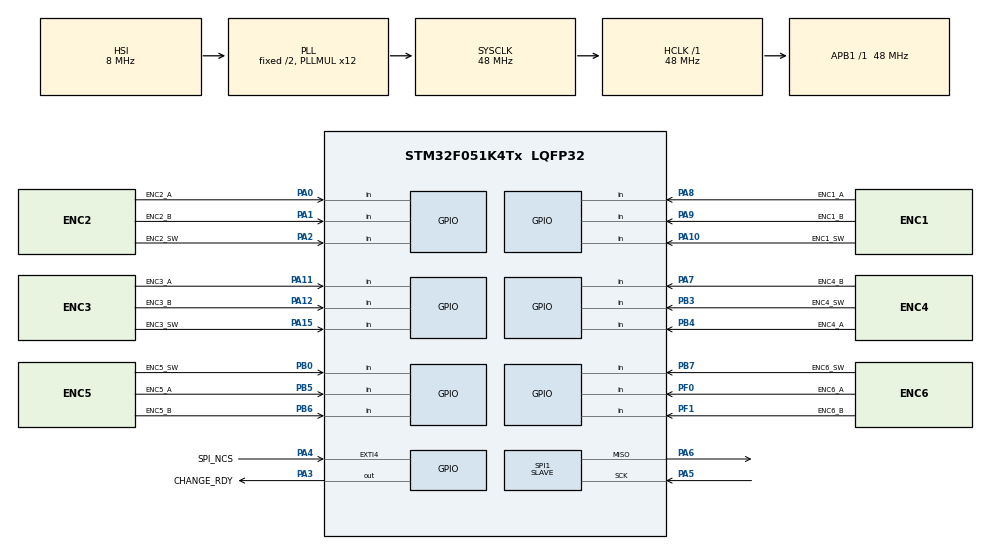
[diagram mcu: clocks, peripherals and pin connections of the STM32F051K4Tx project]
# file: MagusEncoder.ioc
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Dma.Request0=SPI1_TX
Dma.SPI1_TX.0.Direction=DMA_MEMORY_TO_PERIPH
Dma.SPI1_TX.0.Instance=DMA1_Channel3
Dma.SPI1_TX.0.MemDataAlignment=DMA_MDATAALIGN_BYTE
Dma.SPI1_TX.0.MemInc=DMA_MINC_ENABLE
Dma.SPI1_TX.0.Mode=DMA_NORMAL
Dma.SPI1_TX.0.PeriphDataAlignment=DMA_PDATAALIGN_BYTE
Dma.SPI1_TX.0.PeriphInc=DMA_PINC_DISABLE
Dma.SPI1_TX.0.Priority=DMA_PRIORITY_LOW
Mcu.Family=STM32F0
Mcu.Name=STM32F051K4Tx
Mcu.Package=LQFP32
NVIC.DMA1_Channel2_3_IRQn=true\:0\:0\:false\:false\:true\:false\:true
NVIC.EXTI4_15_IRQn=true\:1\:0\:true\:false\:true\:true\:true
NVIC.SPI1_IRQn=true\:1\:0\:true\:false\:true\:true\:true
PA0.GPIO_Label=ENC2_A
PA0.GPIO_PuPd=GPIO_PULLUP
PA0.Signal=GPIO_Input
PA1.GPIO_Label=ENC2_B
PA1.GPIO_PuPd=GPIO_PULLUP
PA1.Signal=GPIO_Input
PA10.GPIO_Label=ENC1_SW
PA10.GPIO_PuPd=GPIO_PULLUP
PA10.Signal=GPIO_Input
PA11.GPIO_Label=ENC3_A
PA11.GPIO_PuPd=GPIO_PULLUP
PA11.Signal=GPIO_Input
PA12.GPIO_Label=ENC3_B
PA12.GPIO_PuPd=GPIO_PULLUP
PA12.Signal=GPIO_Input
PA13.Mode=Serial_Wire
PA13.Signal=SYS_SWDIO
PA14.Mode=Serial_Wire
PA14.Signal=SYS_SWCLK
PA15.GPIO_Label=ENC3_SW
PA15.GPIO_PuPd=GPIO_PULLUP
PA15.Signal=GPIO_Input
PA2.GPIO_Label=ENC2_SW
PA2.GPIO_PuPd=GPIO_PULLUP
PA2.Signal=GPIO_Input
PA3.GPIO_Label=CHANGE_RDY
PA3.PinState=GPIO_PIN_RESET
PA3.Signal=GPIO_Output
PA4.GPIO_Label=SPI_NCS
PA4.GPIO_ModeDefaultEXTI=GPIO_MODE_IT_FALLING
PA4.Signal=GPXTI4
PA5.Mode=TX_Only_Simplex_Unidirect_Slave
PA5.Signal=SPI1_SCK
PA6.Mode=TX_Only_Simplex_Unidirect_Slave
PA6.Signal=SPI1_MISO
PA7.GPIO_Label=ENC4_B
PA7.GPIO_PuPd=GPIO_PULLUP
PA7.Signal=GPIO_Input
PA8.GPIO_Label=ENC1_A
PA8.GPIO_PuPd=GPIO_PULLUP
PA8.Signal=GPIO_Input
PA9.GPIO_Label=ENC1_B
PA9.GPIO_PuPd=GPIO_PULLUP
PA9.Signal=GPIO_Input
PB0.GPIO_Label=ENC5_SW
PB0.GPIO_PuPd=GPIO_PULLUP
PB0.Signal=GPIO_Input
PB3.GPIO_Label=ENC4_SW
PB3.GPIO_PuPd=GPIO_PULLUP
PB3.Signal=GPIO_Input
PB4.GPIO_Label=ENC4_A
PB4.GPIO_PuPd=GPIO_PULLUP
PB4.Signal=GPIO_Input
PB5.GPIO_Label=ENC5_A
PB5.GPIO_PuPd=GPIO_PULLUP
PB5.Signal=GPIO_Input
PB6.GPIO_Label=ENC5_B
PB6.GPIO_PuPd=GPIO_PULLUP
PB6.Signal=GPIO_Input
PB7.GPIO_Label=ENC6_SW
PB7.GPIO_PuPd=GPIO_PULLUP
PB7.Signal=GPIO_Input
PF0-OSC_IN.GPIO_Label=ENC6_A
PF0-OSC_IN.GPIO_PuPd=GPIO_PULLUP
PF0-OSC_IN.Signal=GPIO_Input
PF1-OSC_OUT.GPIO_Label=ENC6_B
PF1-OSC_OUT.GPIO_PuPd=GPIO_PULLUP
PF1-OSC_OUT.Signal=GPIO_Input
ProjectManager.HeapSize=0x200
ProjectManager.StackSize=0x400
ProjectManager.TargetToolchain=MDK-ARM V5
RCC.AHBFreq_Value=48000000
RCC.APB1Freq_Value=48000000
RCC.APB1TimFreq_Value=48000000
RCC.HCLKFreq_Value=48000000
RCC.PLLMUL=RCC_PLL_MUL12
RCC.SYSCLKFreq_VALUE=48000000
RCC.SYSCLKSource=RCC_SYSCLKSOURCE_PLLCLK
SPI1.DataSize=SPI_DATASIZE_8BIT
SPI1.Direction=SPI_DIRECTION_2LINES
SPI1.Mode=SPI_MODE_SLAVE
SPI1.TIMode=SPI_TIMODE_DISABLE
SPI1.VirtualType=VM_SLAVE
board=MagusEncoder

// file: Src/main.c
/* USER CODE BEGIN Header */
/**
  ******************************************************************************
  * @file           : main.c
  * @brief          : Main program body
  ******************************************************************************
  ** This notice applies to any and all portions of this file
  * that are not between comment pairs USER CODE BEGIN and
  * USER CODE END. Other portions of this file, whether
  * inserted by the user or by software development tools
  * are owned by their respective copyright owners.
  *
  * COPYRIGHT(c) 2019 STMicroelectronics
  *
  * Redistribution and use in source and binary forms, with or without modification,
  * are permitted provided that the following conditions are met:
  *   1. Redistributions of source code must retain the above copyright notice,
  *      this list of conditions and the following disclaimer.
  *   2. Redistributions in binary form must reproduce the above copyright notice,
  *      this list of conditions and the following disclaimer in the documentation
  *      and/or other materials provided with the distribution.
  *   3. Neither the name of STMicroelectronics nor the names of its contributors
  *      may be used to endorse or promote products derived from this software
  *      without specific prior written permission.
  *
  * THIS SOFTWARE IS PROVIDED BY THE COPYRIGHT HOLDERS AND CONTRIBUTORS "AS IS"
  * AND ANY EXPRESS OR IMPLIED WARRANTIES, INCLUDING, BUT NOT LIMITED TO, THE
  * IMPLIED WARRANTIES OF MERCHANTABILITY AND FITNESS FOR A PARTICULAR PURPOSE ARE
  * DISCLAIMED. IN NO EVENT SHALL THE COPYRIGHT HOLDER OR CONTRIBUTORS BE LIABLE
  * FOR ANY DIRECT, INDIRECT, INCIDENTAL, SPECIAL, EXEMPLARY, OR CONSEQUENTIAL
  * DAMAGES (INCLUDING, BUT NOT LIMITED TO, PROCUREMENT OF SUBSTITUTE GOODS OR
  * SERVICES; LOSS OF USE, DATA, OR PROFITS; OR BUSINESS INTERRUPTION) HOWEVER
  * CAUSED AND ON ANY THEORY OF LIABILITY, WHETHER IN CONTRACT, STRICT LIABILITY,
  * OR TORT (INCLUDING NEGLIGENCE OR OTHERWISE) ARISING IN ANY WAY OUT OF THE USE
  * OF THIS SOFTWARE, EVEN IF ADVISED OF THE POSSIBILITY OF SUCH DAMAGE.
  *
  ******************************************************************************
  */
/* USER CODE END Header */
#include "main.h"

/* USER CODE BEGIN Includes */
#include "MagusEncoder.h"
/* USER CODE END Includes */

SPI_HandleTypeDef hspi1;
DMA_HandleTypeDef hdma_spi1_tx;

/* USER CODE BEGIN PV */
/* Private variables ---------------------------------------------------------*/

/* USER CODE END PV */

void SystemClock_Config(void);
static void MX_GPIO_Init(void);
static void MX_DMA_Init(void);
static void MX_SPI1_Init(void);
/* USER CODE BEGIN PFP */
/* Private function prototypes -----------------------------------------------*/

/* USER CODE END PFP */

int main(void)
{

  /* MCU Configuration--------------------------------------------------------*/

  /* Reset of all peripherals, Initializes the Flash interface and the Systick. */
  HAL_Init();

  /* Configure the system clock */
  SystemClock_Config();

  /* Initialize all configured peripherals */
  MX_GPIO_Init();
  MX_DMA_Init();
  MX_SPI1_Init();

  /* Infinite loop */
  /* USER CODE BEGIN WHILE */
  while (1)
  {
    Encoders_Main();
    HAL_Delay(1);
    /* USER CODE END WHILE */

  }
}

void SystemClock_Config(void)
{
  RCC_OscInitTypeDef RCC_OscInitStruct = {0};
  RCC_ClkInitTypeDef RCC_ClkInitStruct = {0};

  /** Initializes the RCC Oscillators according to the specified parameters
  * in the RCC_OscInitTypeDef structure.
  */
  RCC_OscInitStruct.OscillatorType = RCC_OSCILLATORTYPE_HSI;
  RCC_OscInitStruct.HSIState = RCC_HSI_ON;
  RCC_OscInitStruct.HSICalibrationValue = RCC_HSICALIBRATION_DEFAULT;
  RCC_OscInitStruct.PLL.PLLState = RCC_PLL_ON;
  RCC_OscInitStruct.PLL.PLLSource = RCC_PLLSOURCE_HSI;
  RCC_OscInitStruct.PLL.PLLMUL = RCC_PLL_MUL12;
  RCC_OscInitStruct.PLL.PREDIV = RCC_PREDIV_DIV1;
  if (HAL_RCC_OscConfig(&RCC_OscInitStruct) != HAL_OK)
  {
    Error_Handler();
  }
  /** Initializes the CPU, AHB and APB buses clocks
  */
  RCC_ClkInitStruct.ClockType = RCC_CLOCKTYPE_HCLK|RCC_CLOCKTYPE_SYSCLK
                              |RCC_CLOCKTYPE_PCLK1;
  RCC_ClkInitStruct.SYSCLKSource = RCC_SYSCLKSOURCE_PLLCLK;
  RCC_ClkInitStruct.AHBCLKDivider = RCC_SYSCLK_DIV1;
  RCC_ClkInitStruct.APB1CLKDivider = RCC_HCLK_DIV1;

  if (HAL_RCC_ClockConfig(&RCC_ClkInitStruct, FLASH_LATENCY_1) != HAL_OK)
  {
    Error_Handler();
  }
}

static void MX_SPI1_Init(void)
{

  /* SPI1 parameter configuration*/
  hspi1.Instance = SPI1;
  hspi1.Init.Mode = SPI_MODE_SLAVE;
  hspi1.Init.Direction = SPI_DIRECTION_2LINES;
  hspi1.Init.DataSize = SPI_DATASIZE_8BIT;
  hspi1.Init.CLKPolarity = SPI_POLARITY_LOW;
  hspi1.Init.CLKPhase = SPI_PHASE_1EDGE;
  hspi1.Init.NSS = SPI_NSS_SOFT;
  hspi1.Init.FirstBit = SPI_FIRSTBIT_MSB;
  hspi1.Init.TIMode = SPI_TIMODE_DISABLE;
  hspi1.Init.CRCCalculation = SPI_CRCCALCULATION_DISABLE;
  hspi1.Init.CRCPolynomial = 7;
  hspi1.Init.CRCLength = SPI_CRC_LENGTH_DATASIZE;
  hspi1.Init.NSSPMode = SPI_NSS_PULSE_DISABLE;
  if (HAL_SPI_Init(&hspi1) != HAL_OK)
  {
    Error_Handler();
  }

}

static void MX_DMA_Init(void)
{

  /* DMA controller clock enable */
  __HAL_RCC_DMA1_CLK_ENABLE();

  /* DMA interrupt init */
  /* DMA1_Channel2_3_IRQn interrupt configuration */
  HAL_NVIC_SetPriority(DMA1_Channel2_3_IRQn, 0, 0);
  HAL_NVIC_EnableIRQ(DMA1_Channel2_3_IRQn);

}

static void MX_GPIO_Init(void)
{
  GPIO_InitTypeDef GPIO_InitStruct = {0};

  /* GPIO Ports Clock Enable */
  __HAL_RCC_GPIOF_CLK_ENABLE();
  __HAL_RCC_GPIOA_CLK_ENABLE();
  __HAL_RCC_GPIOB_CLK_ENABLE();

  /*Configure GPIO pin Output Level */
  HAL_GPIO_WritePin(CHANGE_RDY_GPIO_Port, CHANGE_RDY_Pin, GPIO_PIN_RESET);

  /*Configure GPIO pins : ENC6_A_Pin ENC6_B_Pin */
  GPIO_InitStruct.Pin = ENC6_A_Pin|ENC6_B_Pin;
  GPIO_InitStruct.Mode = GPIO_MODE_INPUT;
  GPIO_InitStruct.Pull = GPIO_PULLUP;
  HAL_GPIO_Init(GPIOF, &GPIO_InitStruct);

  /*Configure GPIO pins : ENC2_A_Pin ENC2_B_Pin ENC2_SW_Pin ENC4_B_Pin
                           ENC1_A_Pin ENC1_B_Pin ENC1_SW_Pin ENC3_A_Pin
                           ENC3_B_Pin ENC3_SW_Pin */
  GPIO_InitStruct.Pin = ENC2_A_Pin|ENC2_B_Pin|ENC2_SW_Pin|ENC4_B_Pin
                          |ENC1_A_Pin|ENC1_B_Pin|ENC1_SW_Pin|ENC3_A_Pin
                          |ENC3_B_Pin|ENC3_SW_Pin;
  GPIO_InitStruct.Mode = GPIO_MODE_INPUT;
  GPIO_InitStruct.Pull = GPIO_PULLUP;
  HAL_GPIO_Init(GPIOA, &GPIO_InitStruct);

  /*Configure GPIO pin : CHANGE_RDY_Pin */
  GPIO_InitStruct.Pin = CHANGE_RDY_Pin;
  GPIO_InitStruct.Mode = GPIO_MODE_OUTPUT_PP;
  GPIO_InitStruct.Pull = GPIO_NOPULL;
  GPIO_InitStruct.Speed = GPIO_SPEED_FREQ_LOW;
  HAL_GPIO_Init(CHANGE_RDY_GPIO_Port, &GPIO_InitStruct);

  /*Configure GPIO pin : SPI_NCS_Pin */
  GPIO_InitStruct.Pin = SPI_NCS_Pin;
  GPIO_InitStruct.Mode = GPIO_MODE_IT_FALLING;
  GPIO_InitStruct.Pull = GPIO_NOPULL;
  HAL_GPIO_Init(SPI_NCS_GPIO_Port, &GPIO_InitStruct);

  /*Configure GPIO pins : ENC5_SW_Pin ENC4_SW_Pin ENC4_A_Pin ENC5_A_Pin
                           ENC5_B_Pin ENC6_SW_Pin */
  GPIO_InitStruct.Pin = ENC5_SW_Pin|ENC4_SW_Pin|ENC4_A_Pin|ENC5_A_Pin
                          |ENC5_B_Pin|ENC6_SW_Pin;
  GPIO_InitStruct.Mode = GPIO_MODE_INPUT;
  GPIO_InitStruct.Pull = GPIO_PULLUP;
  HAL_GPIO_Init(GPIOB, &GPIO_InitStruct);

  /*Configure GPIO pin : PB1 */
  GPIO_InitStruct.Pin = GPIO_PIN_1;
  GPIO_InitStruct.Mode = GPIO_MODE_ANALOG;
  GPIO_InitStruct.Pull = GPIO_NOPULL;
  HAL_GPIO_Init(GPIOB, &GPIO_InitStruct);

  /* EXTI interrupt init*/
  HAL_NVIC_SetPriority(EXTI4_15_IRQn, 1, 0);
  HAL_NVIC_EnableIRQ(EXTI4_15_IRQn);

}

void Error_Handler(void)
{
  /* USER CODE BEGIN Error_Handler_Debug */
#ifdef DEBUG
  __asm__("BKPT");
#else
  NVIC_SystemReset();
#endif
  /* USER CODE END Error_Handler_Debug */
}

#ifdef  USE_FULL_ASSERT
/**
  * @brief  Reports the name of the source file and the source line number
  *         where the assert_param error has occurred.
  * @param  file: pointer to the source file name
  * @param  line: assert_param error line source number
  * @retval None
  */
void assert_failed(uint8_t *file, uint32_t line)
{
  /* USER CODE BEGIN 6 */
#ifdef DEBUG
  __asm__("BKPT");
#else
  NVIC_SystemReset();
#endif
  /* USER CODE END 6 */
}
#endif /* USE_FULL_ASSERT */

/************************ (C) COPYRIGHT STMicroelectronics *****END OF FILE****/
